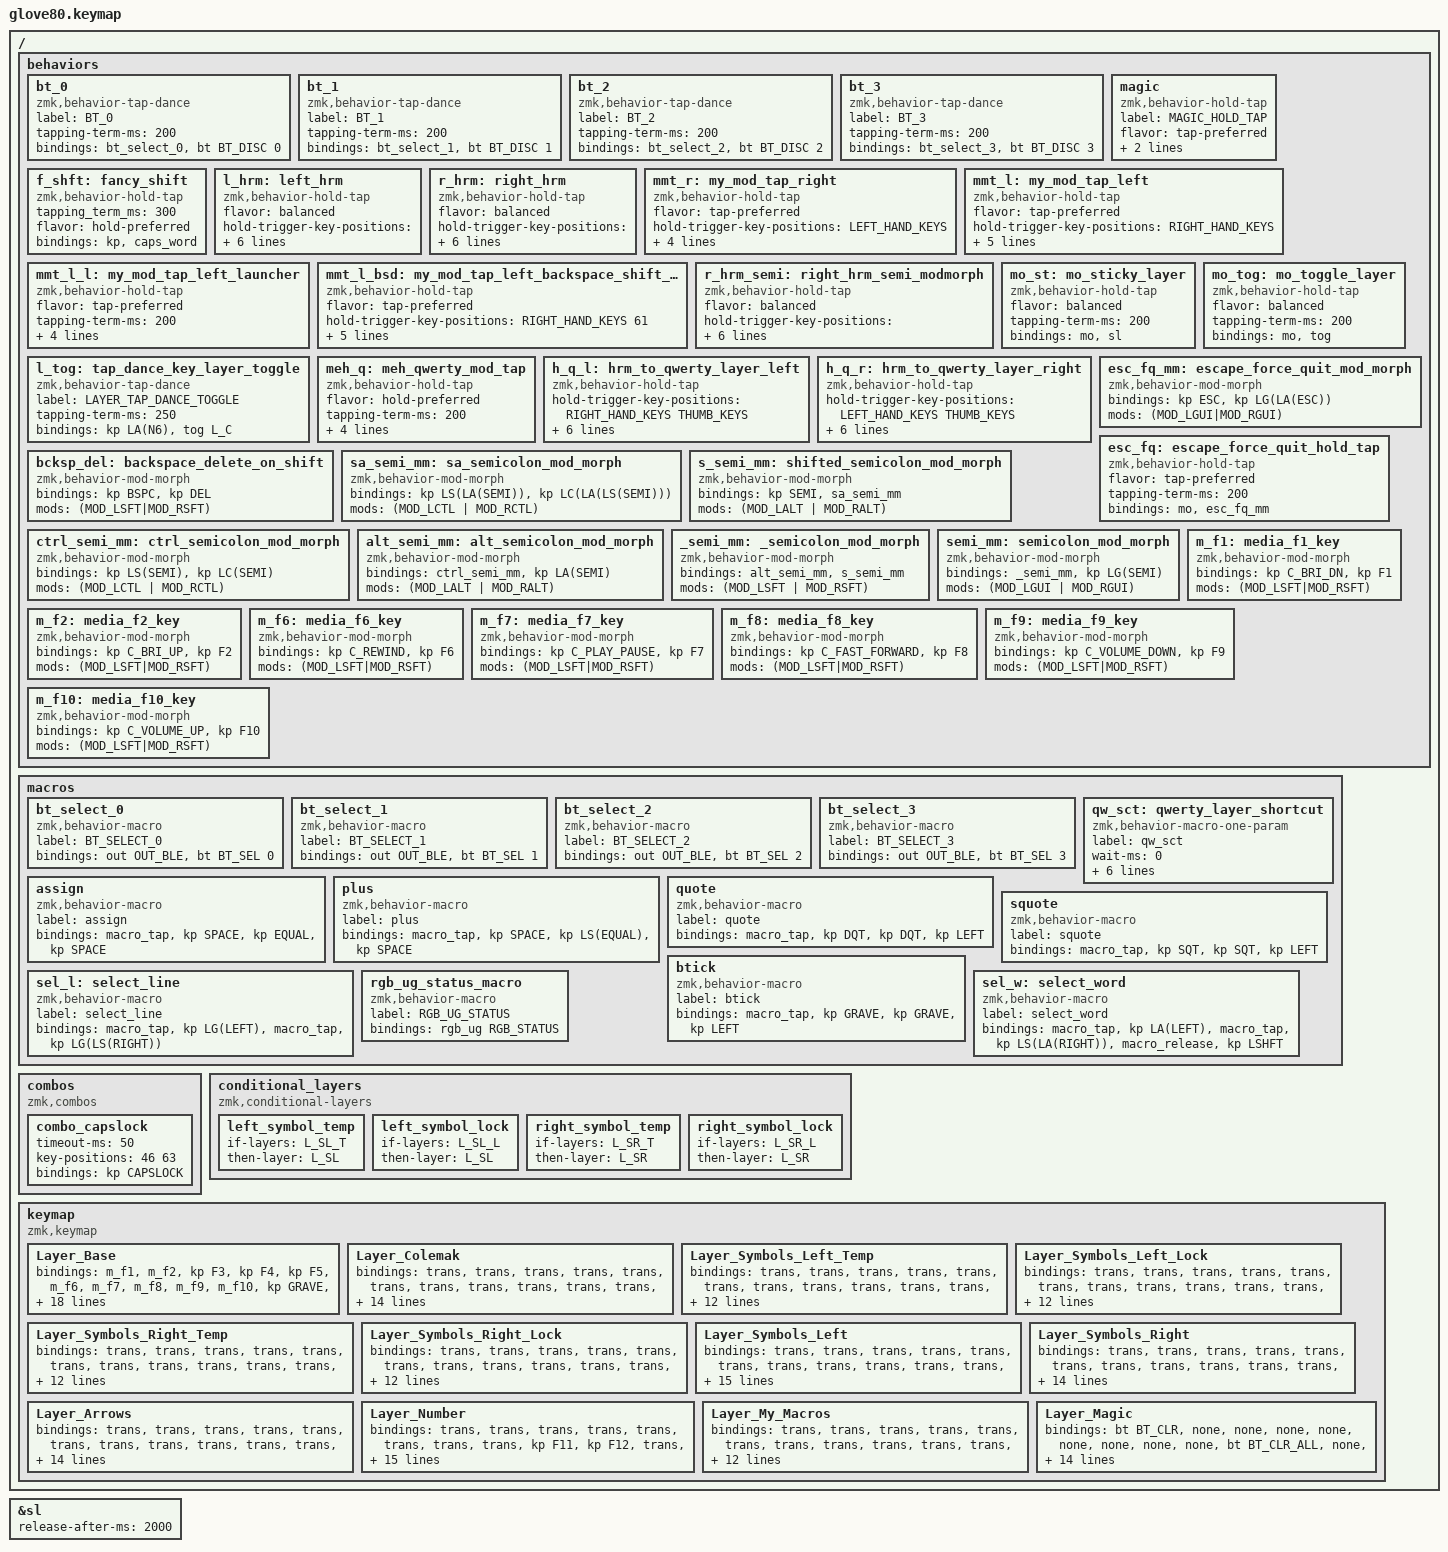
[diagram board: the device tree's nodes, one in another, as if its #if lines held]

/*
 * Copyright (c) 2020 The ZMK Contributors
 * Copyright (c) 2023 Innaworks Development Limited, trading as MoErgo
 *
 * SPDX-License-Identifier: MIT
 */


/* THIS FILE WAS GENERATED BY GLOVE80 LAYOUT EDITOR
 *
 * This file was generated automatically. You may or may not want to
 * edit it directly.
 */

#include <behaviors.dtsi>
/* Include all behaviour includes needed */
#include <dt-bindings/zmk/outputs.h>
#include <dt-bindings/zmk/keys.h>
#include <dt-bindings/zmk/bt.h>
#include <dt-bindings/zmk/rgb.h>

/* Automatically generated layer name #define */
#define L_B 0
#define L_C 1
#define L_SL_T 2
#define L_SL_L 3
#define L_SR_T 4
#define L_SR_L 5
#define L_SL 6
#define L_SR 7
#define L_A 8
#define L_N 9
#define L_MM 10
#define L_M 11

#define HRM_TAPPING_TERM 175
#define HRM_QUICK_TAP 300

/*
 * The order of layers matters here- if we have 'base-like' layer (e.g. colemak) is above the
 * layer we want to go into (e.g. symbol), the base must be lower because they all stack.
 * This also means that we want magic to be (near) last.
 */

/* Custom Device-tree */

/ {
#ifdef BT_DISC_CMD
    behaviors {
        bt_0: bt_0 {
            compatible = "zmk,behavior-tap-dance";
            label = "BT_0";
            #binding-cells = <0>;
            tapping-term-ms = <200>;
            bindings = <&bt_select_0>, <&bt BT_DISC 0>;
        };
        bt_1: bt_1 {
            compatible = "zmk,behavior-tap-dance";
            label = "BT_1";
            #binding-cells = <0>;
            tapping-term-ms = <200>;
            bindings = <&bt_select_1>, <&bt BT_DISC 1>;
        };
        bt_2: bt_2 {
            compatible = "zmk,behavior-tap-dance";
            label = "BT_2";
            #binding-cells = <0>;
            tapping-term-ms = <200>;
            bindings = <&bt_select_2>, <&bt BT_DISC 2>;
        };
        bt_3: bt_3 {
            compatible = "zmk,behavior-tap-dance";
            label = "BT_3";
            #binding-cells = <0>;
            tapping-term-ms = <200>;
            bindings = <&bt_select_3>, <&bt BT_DISC 3>;
        };
    };
    macros {
        bt_select_0: bt_select_0 {
            label = "BT_SELECT_0";
            compatible = "zmk,behavior-macro";
            #binding-cells = <0>;
            bindings
                = <&out OUT_BLE>,
                  <&bt BT_SEL 0>;
        };
        bt_select_1: bt_select_1 {
            label = "BT_SELECT_1";
            compatible = "zmk,behavior-macro";
            #binding-cells = <0>;
            bindings
                = <&out OUT_BLE>,
                  <&bt BT_SEL 1>;
        };
        bt_select_2: bt_select_2 {
            label = "BT_SELECT_2";
            compatible = "zmk,behavior-macro";
            #binding-cells = <0>;
            bindings
                = <&out OUT_BLE>,
                  <&bt BT_SEL 2>;
        };
        bt_select_3: bt_select_3 {
            label = "BT_SELECT_3";
            compatible = "zmk,behavior-macro";
            #binding-cells = <0>;
            bindings
                = <&out OUT_BLE>,
                  <&bt BT_SEL 3>;
        };
    };
#else
    macros {
        bt_0: bt_0 {
            label = "BT_0";
            compatible = "zmk,behavior-macro";
            #binding-cells = <0>;
            bindings
                = <&out OUT_BLE>,
                  <&bt BT_SEL 0>;
        };
        bt_1: bt_1 {
            label = "BT_1";
            compatible = "zmk,behavior-macro";
            #binding-cells = <0>;
            bindings
                = <&out OUT_BLE>,
                  <&bt BT_SEL 1>;
        };
        bt_2: bt_2 {
            label = "BT_2";
            compatible = "zmk,behavior-macro";
            #binding-cells = <0>;
            bindings
                = <&out OUT_BLE>,
                  <&bt BT_SEL 2>;
        };
        bt_3: bt_3 {
            label = "BT_3";
            compatible = "zmk,behavior-macro";
            #binding-cells = <0>;
            bindings
                = <&out OUT_BLE>,
                  <&bt BT_SEL 3>;
        };
    };
#endif
};

/* #define for key positions */
#define POS_LH_T1 52
#define POS_LH_T2 53
#define POS_LH_T3 54
#define POS_LH_T4 69
#define POS_LH_T5 70
#define POS_LH_T6 71
#define POS_LH_C1R2 15
#define POS_LH_C1R3 27
#define POS_LH_C1R4 39
#define POS_LH_C1R5 51
#define POS_LH_C2R1 4
#define POS_LH_C2R2 14
#define POS_LH_C2R3 26
#define POS_LH_C2R4 38
#define POS_LH_C2R5 50
#define POS_LH_C2R6 68
#define POS_LH_C3R1 3
#define POS_LH_C3R2 13
#define POS_LH_C3R3 25
#define POS_LH_C3R4 37
#define POS_LH_C3R5 49
#define POS_LH_C3R6 67
#define POS_LH_C4R1 2
#define POS_LH_C4R2 12
#define POS_LH_C4R3 24
#define POS_LH_C4R4 36
#define POS_LH_C4R5 48
#define POS_LH_C4R6 66
#define POS_LH_C5R1 1
#define POS_LH_C5R2 11
#define POS_LH_C5R3 23
#define POS_LH_C5R4 35
#define POS_LH_C5R5 47
#define POS_LH_C5R6 65
#define POS_LH_C6R1 0
#define POS_LH_C6R2 10
#define POS_LH_C6R3 22
#define POS_LH_C6R4 34
#define POS_LH_C6R5 46
#define POS_LH_C6R6 64
#define POS_RH_T1 57
#define POS_RH_T2 56
#define POS_RH_T3 55
#define POS_RH_T4 74
#define POS_RH_T5 73
#define POS_RH_T6 72
#define POS_RH_C1R2 16
#define POS_RH_C1R3 28
#define POS_RH_C1R4 40
#define POS_RH_C1R5 58
#define POS_RH_C2R1 5
#define POS_RH_C2R2 17
#define POS_RH_C2R3 29
#define POS_RH_C2R4 41
#define POS_RH_C2R5 59
#define POS_RH_C2R6 75
#define POS_RH_C3R1 6
#define POS_RH_C3R2 18
#define POS_RH_C3R3 30
#define POS_RH_C3R4 42
#define POS_RH_C3R5 60
#define POS_RH_C3R6 76
#define POS_RH_C4R1 7
#define POS_RH_C4R2 19
#define POS_RH_C4R3 31
#define POS_RH_C4R4 43
#define POS_RH_C4R5 61
#define POS_RH_C4R6 77
#define POS_RH_C5R1 8
#define POS_RH_C5R2 20
#define POS_RH_C5R3 32
#define POS_RH_C5R4 44
#define POS_RH_C5R5 62
#define POS_RH_C5R6 78
#define POS_RH_C6R1 9
#define POS_RH_C6R2 21
#define POS_RH_C6R3 33
#define POS_RH_C6R4 45
#define POS_RH_C6R5 63
#define POS_RH_C6R6 79

#define MEH LC(LS(LA(LALT)))

&sl {
    release-after-ms = <2000>;
};

/* Custom Defined Behaviors */
/ {
    behaviors {
    // Glove80 key positions index for positional hold-tap
    // - https://discord.com/channels/877392805654306816/937645688244826154/1066713913351221248
    // - https://media.discordapp.net/attachments/937645688244826154/1066713913133121556/image.png
    //
    // |------------------------|------------------------|
    // | LEFT_HAND_KEYS         |        RIGHT_HAND_KEYS |
    // |                        |                        |
    // |  0  1  2  3  4         |          5  6  7  8  9 |
    // | 10 11 12 13 14 15      |      16 17 18 19 20 21 |
    // | 22 23 24 25 26 27      |      28 29 30 31 32 33 |
    // | 34 35 36 37 38 39      |      40 41 42 43 44 45 |
    // | 46 47 48 49 50 51      |      58 59 60 61 62 63 |
    // | 64 65 66 67 68         |         75 76 77 78 79 |
    // |                69 52   |   57 74                |
    // |                 70 53  |  56 73                 |
    // |                  71 54 | 55 72                  |
    // |------------------------|------------------------|
    //
    #define LEFT_HAND_KEYS      \
          0  1  2  3  4         \
         10 11 12 13 14 15      \
         22 23 24 25 26 27      \
         34 35 36 37 38 39      \
         46 47 48 49 50 51      \
         64 65 66 67 68
    #define RIGHT_HAND_KEYS     \
                                           5  6  7  8  9 \
                                       16 17 18 19 20 21 \
                                       28 29 30 31 32 33 \
                                       40 41 42 43 44 45 \
                                       58 59 60 61 62 63 \
                                          75 76 77 78 79
    #define THUMB_KEYS          \
                        69 52       57 74                \
                         70 53     56 73                 \
                          71 54   55 72


    magic: magic {
            compatible = "zmk,behavior-hold-tap";
            label = "MAGIC_HOLD_TAP";
            #binding-cells = <2>;
            flavor = "tap-preferred";
            tapping-term-ms = <200>;
            bindings = <&mo>, <&rgb_ug_status_macro>;
        };

/*
 * hold-tap behaviors:
 * - hold-preferred: triggers hold behavior when tapping term is up or another key is pressed
 * - tap-preferred: triggers the hold behavior when tapping term is up, otherwise tap always
 * - balanced: hold behavior when tapping term is up or another key is pressed and released while key held down
 * - tap-unless-interrupted: hold if another key is pressed before tapping term is up, otherwise tap
 */

    f_shft: fancy_shift {
        compatible = "zmk,behavior-hold-tap";
        #binding-cells = <2>;
        tapping_term_ms = <300>;
        flavor = "hold-preferred";
        bindings = <&kp>, <&caps_word>;
    };

    l_hrm: left_hrm {
        compatible = "zmk,behavior-hold-tap";
        flavor = "balanced"; // produces a "hold" if another key is pressed and released within the tapping-term
        hold-trigger-key-positions = <RIGHT_HAND_KEYS THUMB_KEYS>; // if a key not in the list is pressed before tapping term, it's a tap
        hold-trigger-on-release; // wait for other home row mods, kinda? It's confusing
        require-prior-idle-ms = <50>; // ms after typing to allow HRM- reduces flakiness
        tapping-term-ms = <HRM_TAPPING_TERM>; // ms for same-hand HRM or mod-clicks to work
        quick-tap-ms = <HRM_QUICK_TAP>; // if pressed twice within this many MS, will repeat tap key
        #binding-cells = <2>;
        bindings = <&kp>, <&kp>;
    };

    r_hrm: right_hrm {
        compatible = "zmk,behavior-hold-tap";
        flavor = "balanced";
        hold-trigger-key-positions = <LEFT_HAND_KEYS THUMB_KEYS>;
        hold-trigger-on-release;
        tapping-term-ms = <HRM_TAPPING_TERM>;
        quick-tap-ms = <HRM_QUICK_TAP>;
        require-prior-idle-ms = <50>;
        #binding-cells = <2>;
        bindings = <&kp>, <&kp>;
    };

    // used for mod-taps on right thumb keys
    mmt_r: my_mod_tap_right {
        // generic mod tap for right hand
        compatible = "zmk,behavior-hold-tap";
        flavor = "tap-preferred";
        hold-trigger-key-positions = <LEFT_HAND_KEYS>;
        tapping-term-ms = <200>;
        // no quick tap to allow for quick space-sym-space sequences.
        require-prior-idle-ms = <50>;
        #binding-cells = <2>;
        bindings = <&mo>, <&kp>;
        retro-tap;
    };

    // used for mod-taps on left thumb keys
    mmt_l: my_mod_tap_left {
        // generic mod tap for left hand
        compatible = "zmk,behavior-hold-tap";
        flavor = "tap-preferred";
        hold-trigger-key-positions = <RIGHT_HAND_KEYS>;
        tapping-term-ms = <200>;
        quick-tap-ms = <175>;
        require-prior-idle-ms = <50>;
        #binding-cells = <2>;
        bindings = <&mo>, <&kp>;
        retro-tap;
    };

    mmt_l_l: my_mod_tap_left_launcher {
        // generic mod tap for left hand, launcher
        compatible = "zmk,behavior-hold-tap";
        flavor = "tap-preferred";
        // hold-trigger-key-positions = <RIGHT_HAND_KEYS>;
        tapping-term-ms = <200>;
        quick-tap-ms = <175>;
        require-prior-idle-ms = <50>;
        #binding-cells = <2>;
        bindings = <&kp>, <&kp>;
        retro-tap;
    };

    /*
     * These next two behaviors allow me to have a hrm when held,
     * but some other kind of modmorph / custom behavior when pressed.
     * specific to the backspace thumb key as a mod-tap and mod morph.
    */
    mmt_l_bsd: my_mod_tap_left_backspace_shift_delete {
        // mod tap that triggers a backspace-delete mod morph on tap
        compatible = "zmk,behavior-hold-tap";
        flavor = "tap-preferred";
        hold-trigger-key-positions = <RIGHT_HAND_KEYS 61>; // 61 is the period key, which lets me do a space on the symbol layer
        tapping-term-ms = <200>;
        quick-tap-ms = <175>;
        require-prior-idle-ms = <50>;
        #binding-cells = <2>;
        bindings = <&mo>, <&bcksp_del>;
        retro-tap;
    };

    r_hrm_semi: right_hrm_semi_modmorph {
        compatible = "zmk,behavior-hold-tap";
        flavor = "balanced";
        hold-trigger-key-positions = <LEFT_HAND_KEYS THUMB_KEYS>;
        hold-trigger-on-release;
        tapping-term-ms = <HRM_TAPPING_TERM>;
        quick-tap-ms = <HRM_QUICK_TAP>;
        require-prior-idle-ms = <50>;
        #binding-cells = <2>;
        bindings = <&kp>, <&semi_mm>;
    };

    // &mo to layer on hold, sticky layer on tap
    mo_st: mo_sticky_layer {
            compatible = "zmk,behavior-hold-tap";
            #binding-cells = <2>;
            flavor = "balanced";
            tapping-term-ms = <200>;
            bindings = <&mo>, <&sl>;
    };

    // &mo to layer on hold, toggle layer on tap
    mo_tog: mo_toggle_layer {
            compatible = "zmk,behavior-hold-tap";
            #binding-cells = <2>;
            flavor = "balanced";
            tapping-term-ms = <200>;
            bindings = <&mo>, <&tog>;
    };

    // this is a key that outputs § on tap, toggle colemak layer on double
    l_tog: tap_dance_key_layer_toggle {
            compatible = "zmk,behavior-tap-dance";
            label = "LAYER_TAP_DANCE_TOGGLE";
            #binding-cells = <0>;
            tapping-term-ms = <250>;
            bindings = <&kp LA(N6)>, <&tog L_C>;
     };

    meh_q: meh_qwerty_mod_tap {
            compatible = "zmk,behavior-hold-tap";
            #binding-cells = <2>;
            flavor = "hold-preferred";
            tapping-term-ms = <200>;
            require-prior-idle-ms = <50>; // ms after typing to allow HRM- reduces flakiness
            quick-tap-ms = <400>; // ms for tap key to start repeating
            hold-trigger-on-release; // wait for other home row mods
            bindings = <&qw_sct>, <&kp>;
    };

    // this is basically just a hrm, but the hold binding is the qw_sct macro
    h_q_l: hrm_to_qwerty_layer_left {
            compatible = "zmk,behavior-hold-tap";
            hold-trigger-key-positions = <RIGHT_HAND_KEYS THUMB_KEYS>;
            #binding-cells = <2>;
            flavor = "balanced";
            tapping-term-ms = <200>;
            require-prior-idle-ms = <50>; // ms after typing to allow HRM- reduces flakiness
            quick-tap-ms = <400>; // ms for tap key to start repeating
            tapping-term-ms = <225>; // ms for same-hand HRM to work
            hold-trigger-on-release; // wait for other home row mods
            bindings = <&qw_sct>, <&kp>;
     };

      h_q_r: hrm_to_qwerty_layer_right {
            compatible = "zmk,behavior-hold-tap";
            hold-trigger-key-positions = <LEFT_HAND_KEYS THUMB_KEYS>;
            #binding-cells = <2>;
            flavor = "balanced";
            tapping-term-ms = <200>;
            require-prior-idle-ms = <50>; // ms after typing to allow HRM- reduces flakiness
            quick-tap-ms = <400>; // ms for tap key to start repeating
            tapping-term-ms = <225>; // ms for same-hand HRM to work
            hold-trigger-on-release; // wait for other home row mods
            bindings = <&qw_sct>, <&kp>;
     };

    esc_fq_mm: escape_force_quit_mod_morph {
        compatible = "zmk,behavior-mod-morph";
        #binding-cells = <0>;
        bindings = <&kp ESC>, <&kp LG(LA(ESC))>;
        mods = <(MOD_LGUI|MOD_RGUI)>;
    };

    esc_fq: escape_force_quit_hold_tap {
            compatible = "zmk,behavior-hold-tap";
            #binding-cells = <2>;
            flavor = "tap-preferred";
            tapping-term-ms = <200>;
            bindings = <&mo>, <&esc_fq_mm>;
    };

    bcksp_del: backspace_delete_on_shift {
        compatible = "zmk,behavior-mod-morph";
        #binding-cells = <0>;
        bindings = <&kp BSPC>, <&kp DEL>;
        mods = <(MOD_LSFT|MOD_RSFT)>;
    };

    // if holding shift, alt, and ctrl, output meh(semi)
    // else if just holding shift and alt, output LS(LA(SEMI))
    sa_semi_mm: sa_semicolon_mod_morph {
        compatible = "zmk,behavior-mod-morph";
        #binding-cells = <0>;
        bindings = <&kp LS(LA(SEMI))>, <&kp LC(LA(LS(SEMI)))>;
        mods = <(MOD_LCTL | MOD_RCTL)>;
    };

    // if holding shift and alt, check if holding control
    // if just holding shift, output semicolon
    s_semi_mm: shifted_semicolon_mod_morph {
        compatible = "zmk,behavior-mod-morph";
        #binding-cells = <0>;
        bindings = <&kp SEMI>, <&sa_semi_mm>;
        mods = <(MOD_LALT | MOD_RALT)>;
    };

    // if holding ctrl (and not gui, shift, or alt), LC(SEMI)
    // otherwise, output colon, not semi!
    ctrl_semi_mm: ctrl_semicolon_mod_morph {
        compatible = "zmk,behavior-mod-morph";
        #binding-cells = <0>;
        bindings = <&kp LS(SEMI)>, <&kp LC(SEMI)>;
        mods = <(MOD_LCTL | MOD_RCTL)>;
    };

    // if holding alt (and not gui or shift), LA(SEMI)
    // otherwise check for ctrl
    alt_semi_mm: alt_semicolon_mod_morph {
        compatible = "zmk,behavior-mod-morph";
        #binding-cells = <0>;
        bindings = <&ctrl_semi_mm>, <&kp LA(SEMI)>;
        mods = <(MOD_LALT | MOD_RALT)>;
    };

    // if not shift (and not gui), check if holding alt
    // if holding shift (and not gui), check if holding alt
    _semi_mm: _semicolon_mod_morph {
        compatible = "zmk,behavior-mod-morph";
        #binding-cells = <0>;
        bindings = <&alt_semi_mm>, <&s_semi_mm>;
        mods = <(MOD_LSFT | MOD_RSFT)>;
    };

    // if holding gui only, LG(SEMI)
    semi_mm: semicolon_mod_morph {
        compatible = "zmk,behavior-mod-morph";
        #binding-cells = <0>;
        bindings = <&_semi_mm>, <&kp LG(SEMI)>;
        mods = <(MOD_LGUI | MOD_RGUI)>;
    };

    m_f1: media_f1_key {
        compatible = "zmk,behavior-mod-morph";
        #binding-cells = <0>;
        bindings = <&kp C_BRI_DN>, <&kp F1>;
        mods = <(MOD_LSFT|MOD_RSFT)>;
    };

    m_f2: media_f2_key {
        compatible = "zmk,behavior-mod-morph";
        #binding-cells = <0>;
        bindings = <&kp C_BRI_UP>, <&kp F2>;
        mods = <(MOD_LSFT|MOD_RSFT)>;
    };


    m_f6: media_f6_key {
        compatible = "zmk,behavior-mod-morph";
        #binding-cells = <0>;
        bindings = <&kp C_REWIND>, <&kp F6>;
        mods = <(MOD_LSFT|MOD_RSFT)>;
    };


    m_f7: media_f7_key {
        compatible = "zmk,behavior-mod-morph";
        #binding-cells = <0>;
        bindings = <&kp C_PLAY_PAUSE>, <&kp F7>;
        mods = <(MOD_LSFT|MOD_RSFT)>;
    };


    m_f8: media_f8_key {
        compatible = "zmk,behavior-mod-morph";
        #binding-cells = <0>;
        bindings = <&kp C_FAST_FORWARD>, <&kp F8>;
        mods = <(MOD_LSFT|MOD_RSFT)>;
    };


    m_f9: media_f9_key {
        compatible = "zmk,behavior-mod-morph";
        #binding-cells = <0>;
        bindings = <&kp C_VOLUME_DOWN>, <&kp F9>;
        mods = <(MOD_LSFT|MOD_RSFT)>;
    };

    m_f10: media_f10_key {
        compatible = "zmk,behavior-mod-morph";
        #binding-cells = <0>;
        bindings = <&kp C_VOLUME_UP>, <&kp F10>;
        mods = <(MOD_LSFT|MOD_RSFT)>;
    };
};

    combos {
        compatible = "zmk,combos";
        //  Hold the two shift Homerowmods to generate a capslock keypress
        combo_capslock {
            timeout-ms = <50>;
            key-positions = <46 63>;
            bindings = <&kp CAPSLOCK>;
        };
};
};

/* Automatically generated macro definitions */
/ {
    macros {
    // this is kind of advanced. It's saying;
    // 1. key press the binding param (a HRM)
    // 2. toggle (off) the colemak layer
    // -- stay in this state while macro key is held, and on release:
    // 3. release the HRM
    // 4. re-toggle colemak layer
        qw_sct: qwerty_layer_shortcut {
            label = "qw_sct";
            compatible = "zmk,behavior-macro-one-param";
            #binding-cells = <1>;
            wait-ms = <0>;
            tap-ms = <0>;
            bindings
                = <&macro_param_1to1>
                , <&macro_press &kp MACRO_PLACEHOLDER>
                , <&tog L_C>
                , <&macro_pause_for_release>
                , <&macro_param_1to1>
                , <&macro_release &kp MACRO_PLACEHOLDER>
                , <&macro_tap &tog L_C>
                ;
        };

        assign: assign {
            label = "assign";
            compatible = "zmk,behavior-macro";
            #binding-cells = <0>;
            bindings = <&macro_tap &kp SPACE &kp EQUAL &kp SPACE>;
        };

        plus: plus{
            label = "plus";
            compatible = "zmk,behavior-macro";
            #binding-cells = <0>;
            bindings = <&macro_tap &kp SPACE &kp LS(EQUAL) &kp SPACE>;
        };

        quote: quote{
            label = "quote";
            compatible = "zmk,behavior-macro";
            #binding-cells = <0>;
            bindings = <&macro_tap &kp DQT &kp DQT &kp LEFT>;
        };

        squote: squote{
            label = "squote";
            compatible = "zmk,behavior-macro";
            #binding-cells = <0>;
            bindings = <&macro_tap &kp SQT &kp SQT &kp LEFT> ;
        };

        btick: btick{
            label = "btick";
            compatible = "zmk,behavior-macro";
            #binding-cells = <0>;
            bindings = <&macro_tap &kp GRAVE &kp GRAVE &kp LEFT> ;
        };

        sel_l: select_line {
            label = "select_line";
            compatible = "zmk,behavior-macro";
            #binding-cells = <0>;
            bindings
                = <&macro_tap &kp LG(LEFT)>
                , <&macro_tap &kp LG(LS(RIGHT))>
                ;
        };

       sel_w: select_word {
            label = "select_word";
            compatible = "zmk,behavior-macro";
            #binding-cells = <0>;
           bindings
                = <&macro_tap &kp LA(LEFT)>
                , <&macro_tap &kp LS(LA(RIGHT))>
                , <&macro_release &kp LSHFT>
                ;
        };

        rgb_ug_status_macro: rgb_ug_status_macro {
            label = "RGB_UG_STATUS";
            compatible = "zmk,behavior-macro";
            #binding-cells = <0>;
            bindings
                = <&rgb_ug RGB_STATUS>;
        };
    };
};

/ {
    conditional_layers {
        compatible = "zmk,conditional-layers";
        left_symbol_temp {
            if-layers = <L_SL_T>;
            then-layer = <L_SL>;
        };
        left_symbol_lock {
            if-layers = <L_SL_L>;
            then-layer = <L_SL>;
        };

        right_symbol_temp {
            if-layers = <L_SR_T>;
            then-layer = <L_SR>;
        };
        right_symbol_lock {
            if-layers = <L_SR_L>;
            then-layer = <L_SR>;
        };
    };
};

/* Automatically generated keymap */
/ {
    keymap {
        compatible = "zmk,keymap";

        Layer_Base {
            bindings = <
&m_f1                    &m_f2         &kp F3         &kp F4          &kp F5                                                                                                                                           &m_f6          &m_f7          &m_f8                &m_f9         &m_f10
&kp GRAVE               &kp N1         &kp N2         &kp N3          &kp N4  &kp N5                                                                                                                  &kp N6          &kp N7         &kp N8         &kp N9               &kp N0      &kp MINUS
&mt MEH TAB              &kp Q          &kp W          &kp E           &kp R   &kp T                                                                                                                   &kp Y           &kp U          &kp I          &kp O                &kp P      &kp EQUAL
&esc_fq L_A 0   &l_hrm LCTRL A  &l_hrm LALT S  &l_hrm LGUI D  &l_hrm LSHFT F   &kp G                                                                                                                   &kp H  &r_hrm RSHFT J  &r_hrm RGUI K  &r_hrm RALT L  &r_hrm_semi RCTRL 0        &kp SQT
&f_shft LSHFT 0          &kp Z          &kp X          &kp C           &kp V   &kp B       &mmt_l L_N  TAB             &kp GRAVE  &mo_tog L_N L_N       &kp LGUI  &kp RCTRL  &mmt_r L_MM LG(SPACE)   &kp N           &kp M      &kp COMMA        &kp DOT             &kp FSLH  &mmt_l_l LS(LA(LC(LGUI))) BSLH
&magic L_M 0          &kp HOME      &kp PG_DN      &kp PG_UP         &kp END           &mmt_l_bsd L_SR_T 0  &mmt_l L_A  LA(BSPC)     &kp LG(BSPC)  &kp LG(SPACE)    &kp RET  &mmt_r L_SL_T SPACE                    &kp LEFT       &kp DOWN         &kp UP            &kp RIGHT         &l_tog
            >;
        };

        Layer_Colemak {
            bindings = <
 &trans          &trans         &trans         &trans           &trans                                                                            &trans         &trans         &trans          &trans  &trans
 &trans          &trans         &trans         &trans           &trans  &trans                                                    &trans          &trans         &trans         &trans          &trans  &trans
 &meh_q MEH TAB           &kp Q          &kp W          &kp F           &kp P   &kp B                                                      &kp J           &kp L          &kp U          &kp Y        &semi_mm  &trans
 &trans  &l_hrm LCTRL A  &l_hrm LALT R  &l_hrm LGUI S  &l_hrm LSHFT T   &kp G                                                      &kp M  &r_hrm RSHFT N  &r_hrm RGUI E  &r_hrm RALT I  &r_hrm RCTRL O  &trans
 &trans          &trans         &trans         &trans           &kp D   &kp V    &trans  &trans  &trans  &trans  &trans  &trans    &kp K           &kp H      &kp COMMA        &kp DOT        &kp FSLH  &trans
 &trans          &trans         &trans         &trans           &trans           &trans  &trans  &trans  &trans  &trans  &trans                   &trans         &trans         &trans          &trans  &trans
            >;
        };

         Layer_Symbols_Left_Temp {
            bindings = <
&trans   &trans  &trans  &trans  &trans                                                                     &trans  &trans  &trans  &trans  &trans
&trans   &trans  &trans  &trans  &trans  &trans                                                       &trans  &trans  &trans  &trans  &trans  &trans
&trans   &trans  &trans  &trans  &trans  &trans                                                       &trans  &trans  &trans  &trans  &trans  &trans
&trans   &trans  &trans  &trans  &trans  &trans                                                       &trans  &trans  &trans  &trans  &trans  &trans
&trans   &trans  &trans  &trans  &trans  &trans  &trans   &trans  &trans   &trans  &trans   &trans    &trans  &trans  &trans  &trans  &trans  &trans
&trans   &trans  &trans  &trans  &trans          &trans   &trans  &trans   &trans  &trans   &trans            &trans  &trans  &trans  &trans  &trans
            >;
        };

        Layer_Symbols_Left_Lock {
            bindings = <
&trans   &trans  &trans  &trans  &trans                                                                       &trans  &trans  &trans  &trans  &trans
&trans   &trans  &trans  &trans  &trans  &trans                                                       &trans  &trans  &trans  &trans  &trans  &trans
&trans   &trans  &trans  &trans  &trans  &trans                                                       &trans  &trans  &trans  &trans  &trans  &trans
&trans   &trans  &trans  &trans  &trans  &trans                                                       &trans  &trans  &trans  &trans  &trans  &trans
&trans   &trans  &trans  &trans  &trans  &trans  &trans   &trans  &trans   &trans  &trans   &trans    &trans  &trans  &trans  &trans  &trans  &trans
&trans   &trans  &trans  &trans  &trans          &trans   &trans  &trans   &trans  &trans   &trans             &trans  &trans  &trans  &trans  &trans
            >;
        };

        Layer_Symbols_Right_Temp {
            bindings = <
&trans   &trans  &trans  &trans  &trans                                                                     &trans  &trans  &trans  &trans  &trans
&trans   &trans  &trans  &trans  &trans  &trans                                                     &trans  &trans  &trans  &trans  &trans  &trans
&trans   &trans  &trans  &trans  &trans  &trans                                                     &trans  &trans  &trans  &trans  &trans  &trans
&trans   &trans  &trans  &trans  &trans  &trans                                                     &trans  &trans  &trans  &trans  &trans  &trans
&trans   &trans  &trans  &trans  &trans  &trans  &trans  &trans  &trans   &trans  &trans  &trans    &trans  &trans  &trans  &trans  &trans  &trans
&trans   &trans  &trans  &trans  &trans          &trans  &trans  &trans   &trans  &trans  &trans            &trans  &trans  &trans  &trans  &trans
            >;
        };

        Layer_Symbols_Right_Lock {
            bindings = <
&trans   &trans  &trans  &trans  &trans                                                                       &trans  &trans  &trans  &trans  &trans
&trans   &trans  &trans  &trans  &trans  &trans                                                       &trans  &trans  &trans  &trans  &trans  &trans
&trans   &trans  &trans  &trans  &trans  &trans                                                       &trans  &trans  &trans  &trans  &trans  &trans
&trans   &trans  &trans  &trans  &trans  &trans                                                       &trans  &trans  &trans  &trans  &trans  &trans
&trans   &trans  &trans  &trans  &trans  &trans  &trans   &trans  &trans   &trans  &trans   &trans    &trans  &trans  &trans  &trans  &trans  &trans
&trans   &trans  &trans  &trans  &trans          &trans   &trans  &trans   &trans  &trans   &trans            &trans  &trans  &trans  &trans  &trans
            >;
        };

        Layer_Symbols_Left {
            bindings = <
 &trans              &trans      &trans         &trans         &trans                                                                                     &trans        &trans        &trans     &trans  &trans
 &trans              &trans      &trans         &trans         &trans        &trans                                                         &trans        &trans        &trans        &trans     &trans  &trans
 &kp LS(N6)      &kp LS(N2)  &kp LS(N7)   &kp LS(BSLH)  &kp LS(MINUS)    &kp LS(N4)                                                         &trans        &trans        &trans        &trans     &trans  &trans
 &kp LS(N3)      &kp LS(N1)   &kp GRAVE        &kp SQT        &kp DQT  &kp LS(FSLH)                                                         &trans      &kp RSFT      &kp RGUI      &kp RALT  &kp RCTRL  &trans
 &kp LS(N5)   &kp LS(COMMA)   &kp MINUS      &kp EQUAL    &kp LS(DOT)      &kp BSLH     &trans  &kp SPACE  &trans  &trans  &trans  &trans   &trans   &tog L_SL_L   &tog L_SR_L      &kp SPACE    &trans  &trans
 &trans       &kp LS(GRAVE)  &kp LS(N8)       &kp PLUS       &kp FSLH                  &to L_B     &trans  &trans  &trans  &trans  &to L_B                &trans        &trans         &trans    &trans  &trans
            >;
        };

        Layer_Symbols_Right{
            bindings = <
 &trans     &trans    &trans    &trans      &trans                                                                                &trans       &trans         &trans         &trans   &trans
 &trans     &trans    &trans    &trans      &trans   &trans                                                         &trans        &trans       &trans         &trans         &trans   &trans
 &trans     &trans    &trans    &trans      &trans   &trans                                                         &trans  &kp LS(LBKT)  &kp LS(RBKT)     &kp LG(Z)  &kp LG(LS(Z))   &trans
 &trans  &kp LCTRL  &kp LALT   &kp LGUI  &kp LSHFT   &trans                                                         &trans      &kp LPAR      &kp RPAR      &kp SEMI   &kp LS(SEMI)   &trans
 &trans     &trans  &kp BSPC   &tog L_SL_L   &tog L_SR_L      &trans  &kp BSPC  &trans  &trans  &trans  &trans      &trans        &trans      &kp LBKT      &kp RBKT      &kp SPACE   &trans
 &trans     &trans    &trans    &trans      &trans           &to L_B  &trans    &trans  &trans  &trans  &to L_B                   &trans        &trans        &trans         &trans   &trans
            >;
        };

          Layer_Arrows {
            bindings = <
 &trans     &trans    &trans    &trans     &trans                                                                               &trans        &trans      &trans        &trans   &trans
 &trans     &trans    &trans    &trans     &trans    &trans                                                       &trans        &trans        &trans      &trans        &trans   &trans
 &trans     &trans    &trans    &trans     &trans    &trans                                                    &kp LG(X)  &kp LA(LEFT)  &kp LA(DOWN)  &kp LA(UP) &kp LA(RIGHT)   &trans
 &trans  &kp LCTRL  &kp LALT  &kp LGUI  &kp LSHFT    &trans                                                    &kp LG(C)      &kp LEFT      &kp DOWN      &kp UP     &kp RIGHT   &trans
 &trans     &trans    &trans    &trans     &trans    &trans  &trans  &trans  &trans  &trans  &trans  &trans    &kp LG(V)  &kp LG(LEFT)  &kp LG(DOWN)  &kp LG(UP) &kp LG(RIGHT)   &trans
 &trans     &trans    &trans    &trans     &trans            &trans  &trans  &trans  &trans  &trans  &trans                  &kp LG(Z)        &trans     &trans  &kp LS(LG(Z))   &trans
            >;
        };

        Layer_Number {
            bindings = <
&trans         &trans     &trans  &trans  &trans                                                                          &trans           &trans        &trans          &kp F11   &kp F12
&trans         &trans     &trans  &trans  &trans  &trans                                                          &trans &kp KP_NUM  &kp KP_EQUAL  &kp KP_SLASH  &kp KP_MULTIPLY    &trans
&trans         &trans     &trans  &trans  &trans  &trans                                                          &trans  &kp KP_N7     &kp KP_N8     &kp KP_N9     &kp KP_MINUS    &trans
&trans         &trans     &trans  &trans  &trans  &trans                                                     &kp PERCENT  &kp KP_N4     &kp KP_N5     &kp KP_N6      &kp KP_PLUS    &trans
&trans         &trans     &trans  &trans  &trans  &trans  &trans  &trans  &tog L_N  &trans  &trans  &trans      &kp COMMA  &kp KP_N1     &kp KP_N2     &kp KP_N3           &trans    &trans
&magic L_M 0   &trans     &trans  &trans  &trans          &trans  &trans  &trans   &trans  &trans  &trans                 &kp BSPC      &kp KP_N0    &kp KP_DOT     &kp    COMMA    &trans
            >;
        };

   Layer_My_Macros {
            bindings = <
&trans   &trans  &trans   &trans   &trans                                                                       &trans  &trans  &trans  &trans  &trans
&trans   &trans  &trans   &trans   &trans  &trans                                                       &trans  &trans  &trans  &trans  &trans  &trans
&trans   &trans  &trans   &trans   &trans  &trans                                                       &trans  &trans  &trans  &trans  &trans  &trans
&trans   &trans  &btick  &squote   &quote  &trans                                                       &trans  &trans  &trans  &trans  &trans  &trans
&trans   &sel_l  &sel_w  &assign   &trans  &trans  &trans   &trans  &trans   &trans  &trans   &trans    &trans  &trans  &trans  &trans  &trans  &trans
&trans   &trans  &trans    &plus   &trans          &trans   &trans  &trans   &trans  &trans   &trans            &trans  &trans  &trans  &trans  &trans
            >;
        };

        Layer_Magic {
            bindings = <
  &bt BT_CLR            &none            &none            &none            &none                                                                                  &none   &none   &none   &none  &bt BT_CLR_ALL
       &none            &none            &none            &none            &none            &none                                                         &none   &none   &none   &none   &none           &none
       &none  &rgb_ug RGB_SPI  &rgb_ug RGB_SAI  &rgb_ug RGB_HUI  &rgb_ug RGB_BRI  &rgb_ug RGB_TOG                                                         &none   &none   &none   &none   &none           &none
 &bootloader  &rgb_ug RGB_SPD  &rgb_ug RGB_SAD  &rgb_ug RGB_HUD  &rgb_ug RGB_BRD  &rgb_ug RGB_EFF                                                         &none   &none   &none   &none   &none     &bootloader
  &sys_reset            &none            &none            &none            &none            &none   &bt_2   &bt_3         &none   &none   &none   &none   &none   &none   &none   &none   &none      &sys_reset
       &none            &none            &none            &none            &none                    &bt_0   &bt_1  &out OUT_USB   &none   &none   &none           &none   &none   &none   &none           &none
            >;
        };
    };
};
